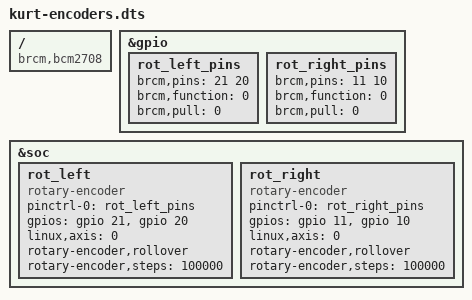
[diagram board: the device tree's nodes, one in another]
/*

Device tree overlay for KURT's 2 rotary encoders.

When this is loaded, 2 new input devices should appear in /dev/input/ (named
"soc:rot_left" and "soc:rot_right"). They can be accessed like any other event
device like a game controller. Use `evtest` to test them.

Sources:
http://www.mjoldfield.com/atelier/2017/03/rpi-devicetree.html
https://github.com/kenrestivo/linux/blob/b74f2674fd49a1d58baf5dbe5f0fbe052b65f873/arch/arm/boot/dts/overlays/rotaries-overlay.dts

*/

/dts-v1/;
/plugin/;

/ {
    /*
    First-gen Pis (A, B, B+, Zero, Compute): BCM2835 chip, BCM2708 family
    Pi 2: BCM2836 chip, BCM2709 family
    Pi 3: BCM2837 chip, BCM2709 family
    This overlay *should* work with all of them. Just bcm2708 should be enough.
    */
    compatible = "brcm,bcm2708";

    fragment@0 {
        target = <&gpio>;
        __overlay__ {
            rot_left_pins: rot_left_pins {
                brcm,pins = <21 20>;    // <A B>
                brcm,function = <0>;    // 0: in, 1: out
                brcm,pull = <0>;        // 0: none, 1: pull-down, 2: pull-up
            };

            rot_right_pins: rot_right_pins {
                brcm,pins = <11 10>;
                brcm,function = <0>;
                brcm,pull = <0>;
            };
        };
    };

    fragment@1 {
        target = <&soc>;
        __overlay__ {
            rot_left: rot_left {
                compatible = "rotary-encoder";
                pinctrl-names = "default";
                pinctrl-0 = <&rot_left_pins>;
                gpios = <&gpio 21 0>, <&gpio 20 0>;
                linux,axis = <0>;   // REL_X / ABS_X
                rotary-encoder,rollover;
                rotary-encoder,steps = <100000>;
            };

            rot_right: rot_right {
                compatible = "rotary-encoder";
                pinctrl-names = "default";
                pinctrl-0 = <&rot_right_pins>;
                gpios = <&gpio 11 0>, <&gpio 10 0>;
                linux,axis = <0>;   // REL_X / ABS_X
                rotary-encoder,rollover;
                rotary-encoder,steps = <100000>;
            };
        };
    };

    // TODO: These overrides could be used to allow external configuration:
    /*
    __overrides__ {
        rot_left_a = <&rot_left_pins>,"bytes.0";
        rot_left_b = <&rot_left_pins>,"bytes.1";
        // TODO: ...
    };
    */
};
